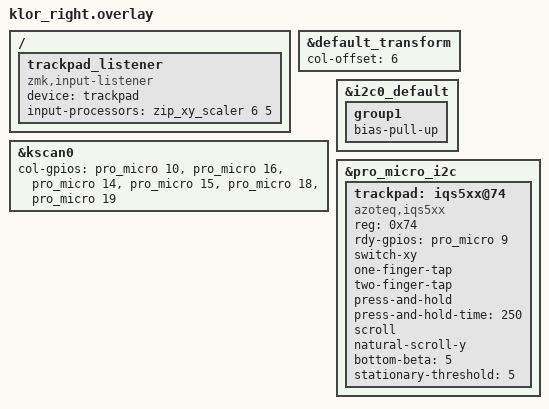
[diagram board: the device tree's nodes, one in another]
/*
 * KLOR polydactyl — rechte Haelfte (Central, mit Azoteq TPS65)
 *
 * Bestueckt: Matrix, Trackpad.
 * Nicht bestueckt: TRRS-Jack, OLED, Buzzer, Encoder.
 *
 * Verdrahtung des TPS65 siehe README.md, Abschnitt "Trackpad anschliessen".
 */

#include "klor.dtsi"
#include <input/processors.dtsi>

&default_transform {
	col-offset = <6>;
};

&kscan0 {
	col-gpios
		= <&pro_micro 10 GPIO_ACTIVE_HIGH>
		, <&pro_micro 16 GPIO_ACTIVE_HIGH>
		, <&pro_micro 14 GPIO_ACTIVE_HIGH>
		, <&pro_micro 15 GPIO_ACTIVE_HIGH>
		, <&pro_micro 18 GPIO_ACTIVE_HIGH>
		, <&pro_micro 19 GPIO_ACTIVE_HIGH>
		;
};

/ {
	trackpad_listener: trackpad_listener {
		compatible = "zmk,input-listener";
		device = <&trackpad>;

		/*
		 * Zeigergeschwindigkeit: 6/5 = +20 %.
		 * zip_xy_scaler skaliert nur die Bewegung, nicht das Scrollen —
		 * dafuer waere zusaetzlich zip_scroll_scaler noetig. Der Prozessor
		 * fuehrt Reste mit (track-remainders), gebrochene Faktoren gehen
		 * also nicht als Rundungsfehler verloren.
		 */
		input-processors = <&zip_xy_scaler 6 5>;
	};
};

/*
 * Interne Pull-ups des nRF52840 auf SDA/SCL zuschalten.
 *
 * ZMKs i2c0_default setzt kein bias-pull-up, und gemessen liegen beide
 * Leitungen im Leerlauf bei 0,5 V statt 3,3 V — ohne High-Pegel kann der
 * IQS5xx die Adresse nicht quittieren, der Treiber meldet dauerhaft
 * NRFX_ERROR_DRV_TWI_ERR_ANACK.
 *
 * Die internen Pull-ups sind mit rund 13 kOhm schwach, reichen fuer die
 * kurze Strecke bei 100 kHz aber meist. Falls nicht: zwei 4,7-kOhm-
 * Widerstaende von SDA und SCL nach 3,3 V, dann kann das hier wieder raus.
 */
&i2c0_default {
	group1 {
		bias-pull-up;
	};
};

&pro_micro_i2c {
	status = "okay";

	trackpad: iqs5xx@74 {
		compatible = "azoteq,iqs5xx";
		reg = <0x74>;
		status = "okay";

		/*
		 * RDY liegt auf dem Buzzer-Pad des KLOR-PCB.
		 * &pro_micro 9 = P1.06 auf dem nice!nano v2.
		 */
		rdy-gpios = <&pro_micro 9 GPIO_ACTIVE_HIGH>;

		/*
		 * NRST ist nicht verdrahtet — der IQS550 hat laut Datenblatt einen
		 * permanenten internen Pull-up ("thus an external component is not
		 * required"). Deshalb kein reset-gpios; der Treiber behandelt die
		 * Property als optional.
		 */

		/*
		 * Das Pad ist quer eingebaut, Kabelabgang links: switch-xy.
		 *
		 * flip-x und flip-y waren zwischenzeitlich gesetzt, drehten die
		 * Richtungen aber genau falsch herum: Finger nach rechts bewegte
		 * den Zeiger nach links, Finger nach oben nach unten. Am Geraet
		 * gemessen, nicht hergeleitet.
		 */
		switch-xy;

		one-finger-tap;
		two-finger-tap;
		press-and-hold;
		press-and-hold-time = <250>;

		scroll;
		natural-scroll-y;

		bottom-beta = <5>;
		stationary-threshold = <5>;
	};
};
